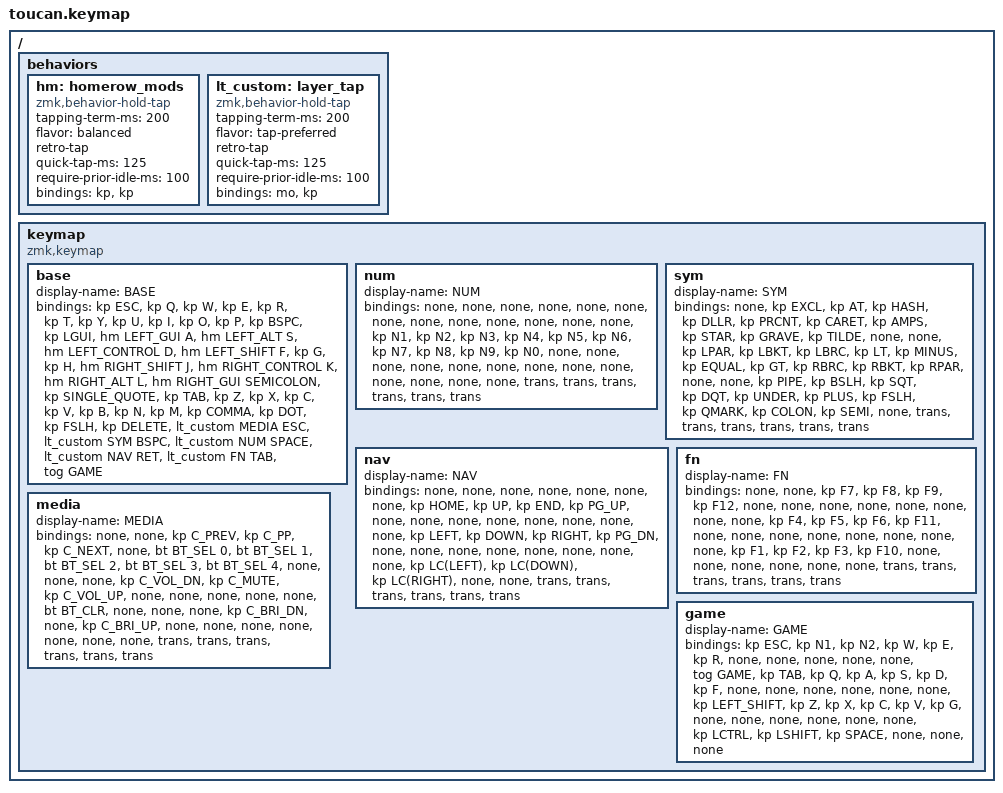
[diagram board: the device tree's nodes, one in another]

#include <behaviors.dtsi>
#include <dt-bindings/zmk/bt.h>
#include <dt-bindings/zmk/keys.h>

#define BASE  0
#define NUM   1
#define SYM   2
#define NAV   3
#define FN    4
#define MEDIA 5
#define GAME  6

/ {
    behaviors {
        // Custom mod-tap behavior with all configurable properties
        hm: homerow_mods {
            compatible = "zmk,behavior-hold-tap";
            #binding-cells = <2>;

            // Time (in ms) you need to hold the key to activate the hold behavior
            // Default is 200ms. Increase if you're getting mods when you want taps.
            tapping-term-ms = <200>;

            // Flavor determines the decision logic for tap vs hold:
            // - "tap-preferred": Prioritize tap, only hold if no other key pressed during tapping-term
            // - "hold-preferred": Prioritize hold if held longer than tapping-term
            // - "balanced": Tap if released before tapping-term, hold if another key pressed during
            // - "tap-unless-interrupted": Always tap unless another key is pressed during tapping-term
            flavor = "balanced";

            // If enabled, tapping the key after the tapping-term will still produce a tap
            // Useful for double-tapping letters quickly
            retro-tap;

            // Time (in ms) to allow quick successive taps without triggering hold
            // If you tap within this time of releasing, it will always tap (useful for rolling keys)
            // Default is disabled (0). Set to 125-200ms to allow quick double-taps.
            quick-tap-ms = <125>;

            // Requires this many ms of idle time before the hold behavior can activate
            // Helps prevent accidental holds when typing fast
            // Default is disabled (0). Try 100-150ms if you get unwanted mods while typing.
            require-prior-idle-ms = <100>;

            // Positional hold-tap: specify key positions that trigger hold when pressed
            // Useful for home row mods - only trigger mod when opposite hand keys are pressed
            // Leave empty to disable, or add an array of key position numbers
            // hold-trigger-key-positions = <>;

            // If true, hold behavior triggers on key release instead of during hold
            // Can make the behavior feel more responsive
            // hold-trigger-on-release;

            bindings = <&kp>, <&kp>;
        };

        // Custom layer-tap behavior with all configurable properties
        lt_custom: layer_tap {
            compatible = "zmk,behavior-hold-tap";
            #binding-cells = <2>;

            // Time (in ms) you need to hold the key to activate the layer
            // Default is 200ms. Increase if you're accidentally activating layers.
            tapping-term-ms = <200>;

            // Flavor determines the decision logic (same options as mod-tap above)
            // For layer-taps, "tap-preferred" or "balanced" are most common
            flavor = "tap-preferred";

            // If enabled, tapping after tapping-term will produce the tap behavior
            retro-tap;

            // Quick-tap allows rapid repeated taps without activating the layer
            // Useful for thumb keys that might be pressed repeatedly
            quick-tap-ms = <125>;

            // Requires idle time before layer activation (helps prevent accidental layer switches)
            require-prior-idle-ms = <100>;

            // Positional hold-tap for layer-taps (less commonly used than with mods)
            // hold-trigger-key-positions = <>;

            bindings = <&mo>, <&kp>;
        };
    };

    keymap {
        compatible = "zmk,keymap";

        base {
            display-name = "BASE";
            bindings = <
&kp ESC  &kp Q  &kp W  &kp E  &kp R  &kp T  &kp Y  &kp U  &kp I  &kp O  &kp P  &kp BSPC  &kp LGUI  &hm LEFT_GUI A  &hm LEFT_ALT S  &hm LEFT_CONTROL D  &hm LEFT_SHIFT F  &kp G  &kp H  &hm RIGHT_SHIFT J  &hm RIGHT_CONTROL K  &hm RIGHT_ALT L  &hm RIGHT_GUI SEMICOLON  &kp SINGLE_QUOTE  &kp TAB  &kp Z  &kp X  &kp C  &kp V  &kp B  &kp N  &kp M  &kp COMMA  &kp DOT  &kp FSLH  &kp DELETE  &lt_custom MEDIA ESC  &lt_custom SYM BSPC  &lt_custom NUM SPACE  &lt_custom NAV RET  &lt_custom FN TAB  &tog GAME
            >;
        };

        num {
            display-name = "NUM";
            bindings = <
&none  &none  &none  &none  &none  &none  &none  &none  &none  &none  &none  &none  &none  &kp N1  &kp N2  &kp N3  &kp N4  &kp N5  &kp N6  &kp N7  &kp N8  &kp N9  &kp N0  &none  &none  &none  &none  &none  &none  &none  &none  &none  &none  &none  &none  &none  &trans  &trans  &trans  &trans  &trans  &trans
            >;
        };

        sym {
            display-name = "SYM";
            bindings = <
&none  &kp EXCL  &kp AT  &kp HASH  &kp DLLR  &kp PRCNT  &kp CARET  &kp AMPS  &kp STAR  &kp GRAVE  &kp TILDE  &none  &none  &kp LPAR  &kp LBKT  &kp LBRC  &kp LT  &kp MINUS  &kp EQUAL  &kp GT  &kp RBRC  &kp RBKT  &kp RPAR  &none  &none  &kp PIPE  &kp BSLH  &kp SQT  &kp DQT  &kp UNDER  &kp PLUS  &kp FSLH  &kp QMARK  &kp COLON  &kp SEMI  &none  &trans  &trans  &trans  &trans  &trans  &trans
            >;
        };

        nav {
            display-name = "NAV";
            bindings = <
&none  &none  &none  &none  &none  &none  &none  &kp HOME  &kp UP  &kp END  &kp PG_UP  &none  &none  &none  &none  &none  &none  &none  &none  &kp LEFT  &kp DOWN  &kp RIGHT  &kp PG_DN  &none  &none  &none  &none  &none  &none  &none  &none  &kp LC(LEFT)  &kp LC(DOWN)  &kp LC(RIGHT)  &none  &none  &trans  &trans  &trans  &trans  &trans  &trans
            >;
        };

        fn {
            display-name = "FN";
            bindings = <
&none  &none  &kp F7  &kp F8  &kp F9  &kp F12  &none  &none  &none  &none  &none  &none  &none  &none  &kp F4  &kp F5  &kp F6  &kp F11  &none  &none  &none  &none  &none  &none  &none  &none  &kp F1  &kp F2  &kp F3  &kp F10  &none  &none  &none  &none  &none  &none  &trans  &trans  &trans  &trans  &trans  &trans
            >;
        };

        media {
            display-name = "MEDIA";
            bindings = <
&none  &none  &kp C_PREV  &kp C_PP  &kp C_NEXT  &none  &bt BT_SEL 0  &bt BT_SEL 1  &bt BT_SEL 2  &bt BT_SEL 3  &bt BT_SEL 4  &none  &none  &none  &kp C_VOL_DN  &kp C_MUTE  &kp C_VOL_UP  &none  &none  &none  &none  &none  &bt BT_CLR  &none  &none  &none  &kp C_BRI_DN  &none  &kp C_BRI_UP  &none  &none  &none  &none  &none  &none  &none  &trans  &trans  &trans  &trans  &trans  &trans
            >;
        };

        game {
            display-name = "GAME";
            bindings = <
&kp ESC  &kp N1  &kp N2  &kp W  &kp E  &kp R  &none  &none  &none  &none  &none  &tog GAME  &kp TAB  &kp Q  &kp A  &kp S  &kp D  &kp F  &none  &none  &none  &none  &none  &none  &kp LEFT_SHIFT  &kp Z  &kp X  &kp C  &kp V  &kp G  &none  &none  &none  &none  &none  &none  &kp LCTRL  &kp LSHIFT  &kp SPACE  &none  &none  &none
            >;
        };
    };
};
